# AST1080 register map
File version: 1.0
CPU: CM4 r0p1, little endian, MPU, FPU, 4 interrupt priority bits, 256 interrupts
Registers are 32-bit, read-write, reset 0x0 unless marked. A register's access mark holds for its fields unless they carry their own. Offsets are from the block's base; [hi:lo] are bit positions; {n}, {i} and the like mark numbered series.

## uart
Base 0x74C33000
Same registers: uart1 0x74C33100, uart2 0x74C33200, uart3 0x74C33300, uart4 0x74C33400, uart5 0x74C33C00
0x00 UARTRBR — Receiving Buffer Register (DLAB = 0)
  [7:0] UARTRBR ro — Receiving Buffer Register
  [7:0] UARTTHR — Transmit Holding Register
0x00 UARTTHR — Transmit Holding Register (DLAB = 0)
  [7:0] UARTRBR1 ro — Receiving Buffer Register
  [7:0] UARTTHR1 — Transmit Holding Register
0x00 UARTDLL — Divisor Latch Low Register : (DLAB = 1)
  [7:0] TheLSBOfTheBdDivisorLatch — The LSB of the baud-rate divisor latch.
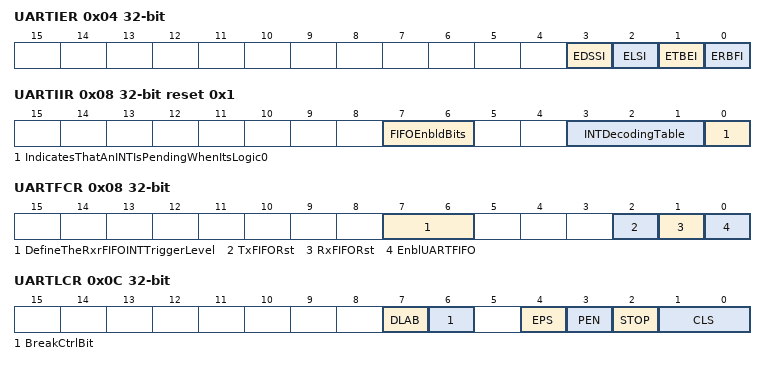
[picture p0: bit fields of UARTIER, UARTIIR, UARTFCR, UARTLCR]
0x04 UARTIER — Interrupt Enable Register (DLAB = 0)
  [3] EDSSI — Enable Modem Status Interrupt
  [2] ELSI — Enable Receiver Line Status Interrupt
  [1] ETBEI — Enable Transmitter Holding Register Empty Interrupt
  [0] ERBFI — Enable Received Data Available Interrupt
0x04 UARTDLH — Divisor Latch High Register : (DLAB = 1)
  [7:0] TheMSBOfTheBdDivisorLatch — The MSB of the baud-rate divisor latch.
0x08 UARTIIR reset 0x1 — Interrupt Identity Register
  [7:6] FIFOEnbldBits ro — FIFO-Enabled Bits
  [3:1] INTDecodingTable ro — Interrupt Decoding Table
  [0] IndicatesThatAnINTIsPendingWhenItsLogic0 ro — Indicates that an interrupt is pending when it's logic "0".
0x08 UARTFCR — FIFO Control Register
  [7:6] DefineTheRxrFIFOINTTriggerLevel — Define the Receiver FIFO Interrupt trigger level.
  [2] TxFIFORst — Transmit FIFO Reset
  [1] RxFIFORst — Receive FIFO Reset
  [0] EnblUARTFIFO — Enable UART FIFO
0x0C UARTLCR — Line Control Register
  [7] DLAB — Divisor latch access bit
  [6] BreakCtrlBit — Break Control bit.
  [4] EPS — Parity mode selection
  [3] PEN — Enable parity bit
  [2] STOP — Number of stop bits transmitted
  [1:0] CLS — Select number of bits per character
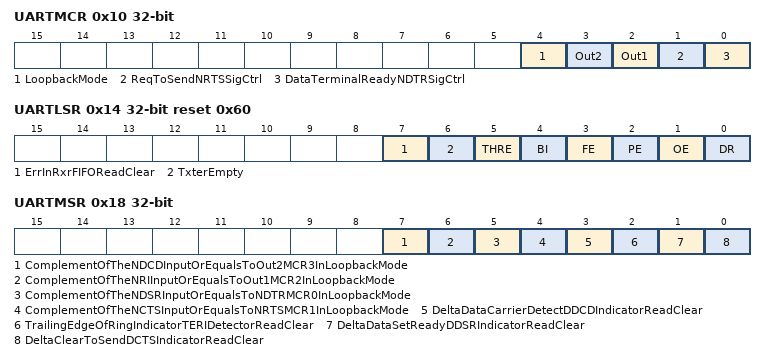
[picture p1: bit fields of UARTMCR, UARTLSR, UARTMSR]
0x10 UARTMCR — Modem Control Register
  [4] LoopbackMode
  [3] Out2
  [2] Out1
  [1] ReqToSendNRTSSigCtrl — Request To Send (nRTS) signal control.
  [0] DataTerminalReadyNDTRSigCtrl — Data Terminal Ready (nDTR) signal control.
0x14 UARTLSR reset 0x60 — Line Status Register
  [7] ErrInRxrFIFOReadClear ro — Error in Receiver FIFO (Read clear)
  [6] TxterEmpty ro — Transmitter empty
  [5] THRE ro — Transmitter holding register empty
  [4] BI ro — Break interrupt (Read clear)
  [3] FE ro — Framing error (Read clear)
  [2] PE ro — Parity error (Read clear)
  [1] OE ro — Overrun error (Read clear)
  [0] DR ro — Data ready
0x18 UARTMSR — Modem Status Register
  [7] ComplementOfTheNDCDInputOrEqualsToOut2MCR3InLoopbackMode ro, [6] ComplementOfTheNRIInputOrEqualsToOut1MCR2InLoopbackMode ro, [5] ComplementOfTheNDSRInputOrEqualsToNDTRMCR0InLoopbackMode ro, [4] ComplementOfTheNCTSInputOrEqualsToNRTSMCR1InLoopbackMode ro, [3] DeltaDataCarrierDetectDDCDIndicatorReadClear ro, [2] TrailingEdgeOfRingIndicatorTERIDetectorReadClear ro, [1] DeltaDataSetReadyDDSRIndicatorReadClear ro, [0] DeltaClearToSendDCTSIndicatorReadClear ro
0x1C UARTSCR — Scratch Register
  [7:0] ScratchBits

## i2cglobal
Base 0x74C0F000
0x00 I2CGLOBAL000 — Device Master Mode Interrupt Status Register
  [15:0] I2CMIRQ ro
0x04 I2CGLOBAL004 — Device Slave Mode Interrupt Status Register
  [15:0] I2CSIRQ ro
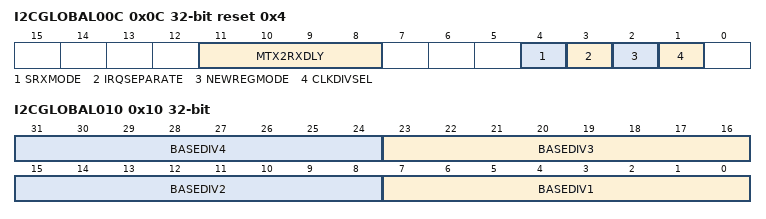
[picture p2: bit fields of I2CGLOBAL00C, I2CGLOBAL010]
0x0C I2CGLOBAL00C reset 0x4 — Global Control Register
  [11:8] MTX2RXDLY, [4] SRXMODE, [3] IRQSEPARATE, [2] NEWREGMODE ro, [1] CLKDIVSEL
0x10 I2CGLOBAL010 — New Clock Divider Control Register
  [8n-1:8n-8] BASEDIV{n} (n=1..4)
0x14 I2CGLOBAL014 reset 0x66666666 — I2CG\_FIFO\_CFG0
  [31:0] FIFOCFG0
0x18 I2CGLOBAL018 reset 0x66666666 — I2CG\_FIFO\_CFG1
  [31:0] FIFOCFG1
0x1C I2CGLOBAL01C — I2CG\_MARB\_CFG
  [31:0] XARBCFG
0x20 I2CGLOBAL020 — Write lock protection Register for Security
  [3:0] GWLOCK

## i2c
Base 0x74C0F100
Same registers: i2c{n} {0x74C0F100+0x100*n} (n=1..13)
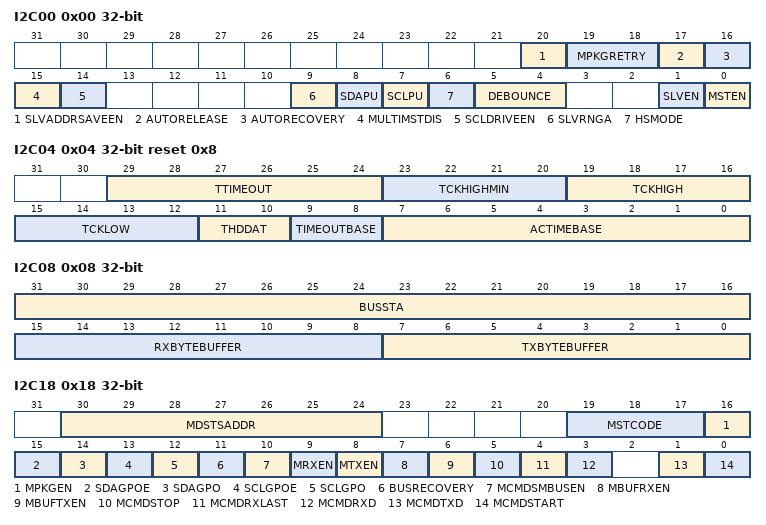
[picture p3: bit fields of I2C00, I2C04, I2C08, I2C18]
0x00 I2C00 — Master/Slave Function Control Register
  [20] SLVADDRSAVEEN, [19:18] MPKGRETRY, [17] AUTORELEASE, [16] AUTORECOVERY, [15] MULTIMSTDIS, [14] SCLDRIVEEN, [9] SLVRNGA, [8] SDAPU, [7] SCLPU, [6] HSMODE, [5:4] DEBOUNCE, [1] SLVEN, [0] MSTEN
0x04 I2C04 reset 0x8 — Master/Slave Clock and AC Timing Control Register
  [29:24] TTIMEOUT, [23:20] TCKHIGHMIN, [19:16] TCKHIGH, [15:12] TCKLOW, [11:10] THDDAT, [9:8] TIMEOUTBASE, [7:0] ACTIMEBASE
0x08 I2C08 — Master/Slave Transmit/Receive Byte Buffer Register
  [31:16] BUSSTA ro, [15:8] RXBYTEBUFFER ro, [7:0] TXBYTEBUFFER ro
0x0C I2C0C — I2CC\_BUFCTL
  [31:0] BUFCTL
0x10 I2C10 — Master Interrupt Control Register
  [31:0] MIRQEN
0x14 I2C14 — Master Interrupt Status Register
  [31:0] MIRQSTA
0x18 I2C18 — Master Command/Status Register
  [30:24] MDSTSADDR, [19:17] MSTCODE, [16] MPKGEN, [15] SDAGPOE, [14] SDAGPO, [13] SCLGPOE, [12] SCLGPO, [11] BUSRECOVERY, [10] MCMDSMBUSEN, [9] MRXEN, [8] MTXEN, [7] MBUFRXEN, [6] MBUFTXEN, [5] MCMDSTOP, [4] MCMDRXLAST, [3] MCMDRXD, [1] MCMDTXD, [0] MCMDSTART
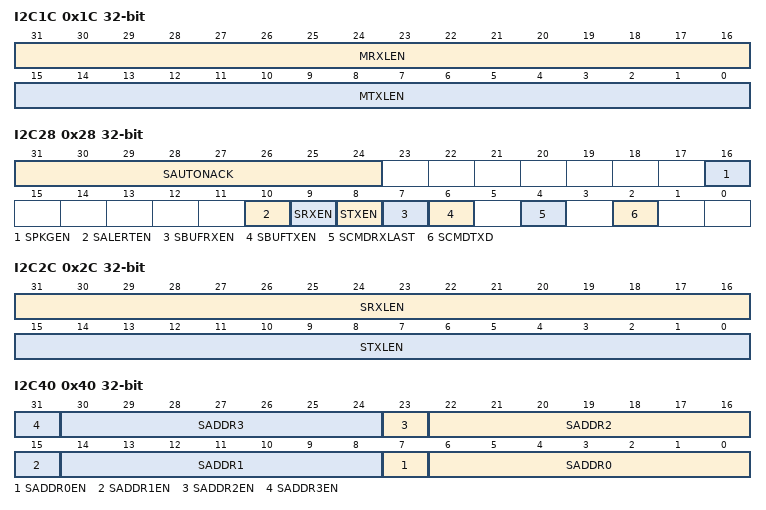
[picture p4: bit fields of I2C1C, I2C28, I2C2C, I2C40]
0x1C I2C1C — Master DMA Buffer Length Register
  [31:16] MRXLEN, [15:0] MTXLEN
0x20 I2C20 — Slave Interrupt Control Register
  [31:0] SIRQEN
0x24 I2C24 — Slave Interrupt Status Register
  [31:0] SIRQSTA
0x28 I2C28 — Slave Command/Status Register
  [31:24] SAUTONACK, [16] SPKGEN, [10] SALERTEN, [9] SRXEN, [8] STXEN, [7] SBUFRXEN, [6] SBUFTXEN, [4] SCMDRXLAST, [2] SCMDTXD
0x2C I2C2C — Slave DMA Buffer Length Register
  [31:16] SRXLEN, [15:0] STXLEN
0x30 I2C30 — Master DMA Mode Tx Buffer Base Address
  [31:0] MTXA
0x34 I2C34 — Master DMA Mode Rx Buffer Base Address
  [31:0] MRXA
0x38 I2C38 — Slave DMA Mode Tx Buffer Base Address
  [31:0] STXA
0x3C I2C3C — Slave DMA Mode Rx Buffer Base Address
  [31:0] SRXA
0x40 I2C40 — Slave Device Address Register
  [8n+7] SADDR{n}EN (n=0..3), [8n+6:8n] SADDR{n} (n=0..3)
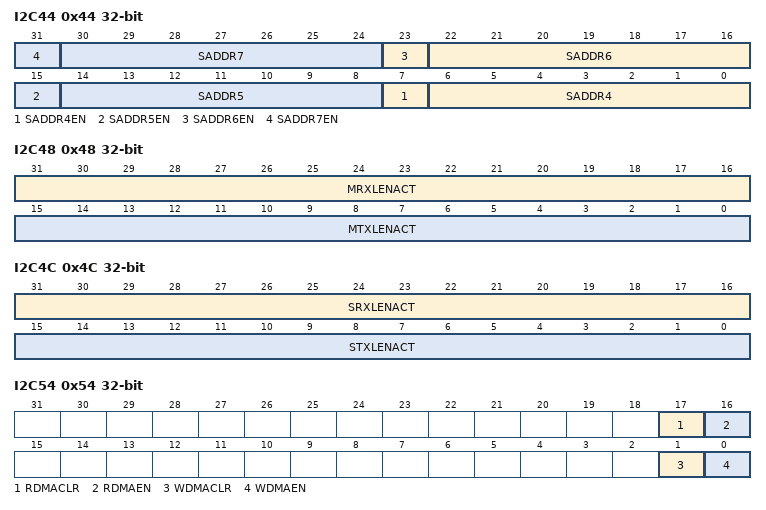
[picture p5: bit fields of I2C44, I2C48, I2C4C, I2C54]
0x44 I2C44 — Slave Device Address Register (extra)
  [8n-25] SADDR{n}EN (n=4..7), [8n-26:8n-32] SADDR{n} (n=4..7)
0x48 I2C48 — Master DMA Length Status Register
  [31:16] MRXLENACT, [15:0] MTXLENACT
0x4C I2C4C — Slave DMA Length Status Register
  [31:16] SRXLENACT, [15:0] STXLENACT
0x50 I2C50 reset 0x404 — I2CC\_DMA\_CFG
  [31:0] DMACFG
0x54 I2C54 — I2CC\_DMA\_STA
  [17] RDMACLR, [16] RDMAEN, [1] WDMACLR, [0] WDMAEN
0x60 I2C60 — Master DMA Mode Tx Buffer Base Address[39:32]
  [7:0] MTXAHI
0x64 I2C64 — Master DMA Mode Rx Buffer Base Address[39:32]
  [7:0] MRXAHI
0x68 I2C68 — Slave DMA Mode Tx Buffer Base Address[39:32]
  [7:0] STXAHI
0x6C I2C6C — Slave DMA Mode Rx Buffer Base Address[39:32]
  [7:0] SRXAHI
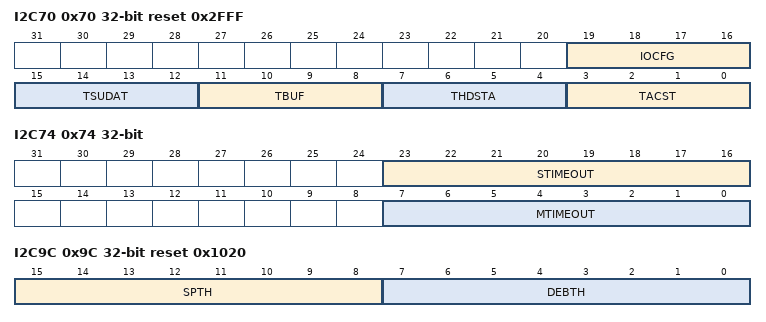
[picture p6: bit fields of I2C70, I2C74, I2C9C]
0x70 I2C70 reset 0x2FFF — MISC configuration for AC timing0
  [19:16] IOCFG, [15:12] TSUDAT, [11:8] TBUF, [7:4] THDSTA, [3:0] TACST
0x74 I2C74 — MISC configuration for AC timing1
  [23:16] STIMEOUT, [7:0] MTIMEOUT
0x78 I2C78 — Debug information for device
  [31:0] SERIALSTATUS ro
0x7C I2C7C reset 0xEFF000 — I2CC\_HS\_ACTIME
  [31:0] HSACTIME
0x80 I2C80 — Recorder information for Slave address matching
  [31:0] SADDRLOG
0x84 I2C84 — Recorder information for Byte transfer
  [31:0] SBYTELOG
0x88 I2C88 — I2CC\_MIRQ\_LOG
  [15:0] MIRQLOG ro
0x8C I2C8C — I2CC\_SIRQ\_LOG
  [15:0] SIRQLOG ro
0x90 I2C90 — I2CC\_WLOCK
  [31:0] WLOCK
0x94 I2C94 reset 0xFFFFFFFF — I2CC\_VERSION\_CTL
  [31:0] FUNCCFG
0x98 I2C98 — I2CM\_MCMDQ
  [31:0] MCMDQ
0x9C I2C9C reset 0x1020 — I2CC\_MISC2
  [15:8] SPTH, [7:0] DEBTH
